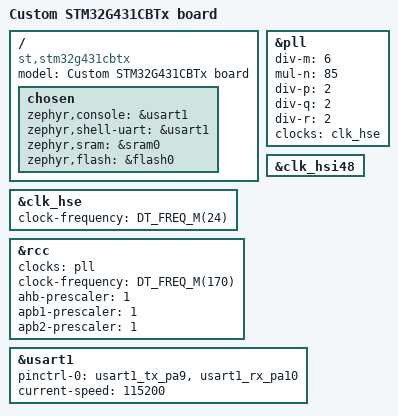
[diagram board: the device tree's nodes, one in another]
/*
 * SPDX-License-Identifier: Apache-2.0
 *
 * Custom board definition for STM32G431CBTx (48-pin LQFP).
 */

/dts-v1/;
#include <st/g4/stm32g431Xb.dtsi>
#include <st/g4/stm32g431c(6-8-b)tx-pinctrl.dtsi>

/ {
	model = "Custom STM32G431CBTx board";
	compatible = "st,stm32g431cbtx";

	chosen {
		zephyr,console = &usart1;
		zephyr,shell-uart = &usart1;
		zephyr,sram = &sram0;
		zephyr,flash = &flash0;
	};
};

/* HSE 24MHz → PLL（/6 ×85 /2）→ SYSCLK 170MHz（G431 上限） */
&clk_hse {
	clock-frequency = <DT_FREQ_M(24)>;
	status = "okay";
};

&pll {
	div-m = <6>;
	mul-n = <85>;
	div-p = <2>;
	div-q = <2>;
	div-r = <2>;
	clocks = <&clk_hse>;
	status = "okay";
};

&rcc {
	clocks = <&pll>;
	clock-frequency = <DT_FREQ_M(170)>;
	ahb-prescaler = <1>;
	apb1-prescaler = <1>;
	apb2-prescaler = <1>;
};

/* USB 的 48MHz 时钟源 = HSI48（RCC_CCIPR.CLK48SEL 复位值 00，开 HSI48 即可） */
&clk_hsi48 {
	status = "okay";
};

&usart1 {
	pinctrl-0 = <&usart1_tx_pa9 &usart1_rx_pa10>;
	pinctrl-names = "default";
	current-speed = <115200>;
	status = "okay";
};
